# S1C31W74 register map
Vendor: Epson; Series: S1C31W74; File version: 1.11
CPU: CM0PLUS r0p1, little endian, MPU, no FPU, VTOR, 2 interrupt priority bits
Registers are 16-bit, read-write, reset 0x0 unless marked. A register's access mark holds for its fields unless they carry their own. Offsets are from the block's base; [hi:lo] are bit positions; {n}, {i} and the like mark numbered series; 'fields as' and 'values as' point back to an identical list.

## UPMUX — Universal port multiplexer control
Base 0x40000300
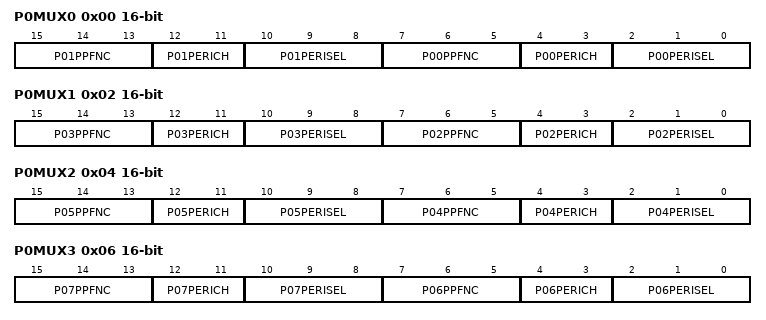
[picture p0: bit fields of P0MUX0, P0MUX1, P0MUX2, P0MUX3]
0x00 P0MUX0 — P00_01 Universal Port Multiplexer Setting Register
  [15:13] P01PPFNC — Assign pin function
  [12:11] P01PERICH — Assign Peripheral channel
  [10:8] P01PERISEL — Assign peripheral
  [7:5] P00PPFNC — Assign pin function
  [4:3] P00PERICH — Assign Peripheral channel
  [2:0] P00PERISEL — Assign peripheral
0x02 P0MUX1 — P02_03 Universal Port Multiplexer Setting Register
  [15:13] P03PPFNC — Assign pin function
  [12:11] P03PERICH — Assign peripheral channel
  [10:8] P03PERISEL — Assign peripheral
  [7:5] P02PPFNC — Assign pin function
  [4:3] P02PERICH — Assign Peripheral channel
  [2:0] P02PERISEL — Assign peripheral
0x04 P0MUX2 — P04_05 Universal Port Multiplexer Setting Register
  [15:13] P05PPFNC — Assign pin function
  [12:11] P05PERICH — Assign Peripheral channel
  [10:8] P05PERISEL — Assign peripheral
  [7:5] P04PPFNC — Assign pin function
  [4:3] P04PERICH — Assign Peripheral channel
  [2:0] P04PERISEL — Assign peripheral
0x06 P0MUX3 — P06_07 Universal Port Multiplexer Setting Register
  [15:13] P07PPFNC — Assign pin function
  [12:11] P07PERICH — Assign Peripheral channel
  [10:8] P07PERISEL — Assign peripheral
  [7:5] P06PPFNC — Assign pin function
  [4:3] P06PERICH — Assign Peripheral channel
  [2:0] P06PERISEL — Assign peripheral
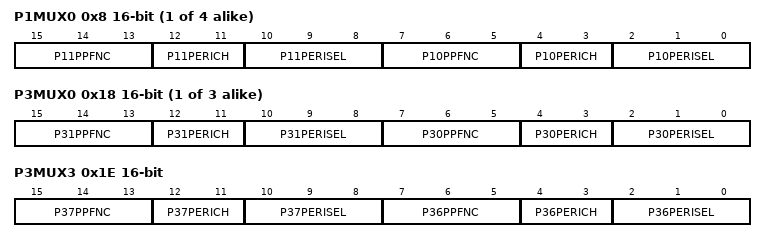
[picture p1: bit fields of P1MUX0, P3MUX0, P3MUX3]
{0x8+2i} P1MUX{i} (i=0..3) — P{2i+10}_{2i+11} Universal Port Multiplexer Setting Register
  [15:13] P{2i+11}PPFNC — Assign pin function
  [12:11] P{2i+11}PERICH — Assign Peripheral channel
  [10:8] P{2i+11}PERISEL — Assign peripheral
  [7:5] P{2i+10}PPFNC — Assign pin function
  [4:3] P{2i+10}PERICH — Assign Peripheral channel
  [2:0] P{2i+10}PERISEL — Assign peripheral
{0x18+2i} P3MUX{i} (i=0..2) — P{2i+30}_{2i+31} Universal Port Multiplexer Setting Register
  [15:13] P{2i+31}PPFNC — Assign pin function
  [12:11] P{2i+31}PERICH — Assign peripheral channel
  [10:8] P{2i+31}PERISEL — Assign peripheral
  [7:5] P{2i+30}PPFNC — Assign pin function
  [4:3] P{2i+30}PERICH — Assign peripheral channel
  [2:0] P{2i+30}PERISEL — Assign peripheral
0x1E P3MUX3 — P36_37 Universal Port Multiplexer Setting Register
  [15:13] P37PPFNC — Assign pin function
  [12:11] P37PERICH — Assign Peripheral channel
  [10:8] P37PERISEL — Assign peripheral
  [7:5] P36PPFNC — Assign pin function
  [4:3] P36PERICH — Assign Peripheral channel
  [2:0] P36PERISEL — Assign peripheral

## SPIA_0 — Synchronous serial interface control
Base 0x400003B0
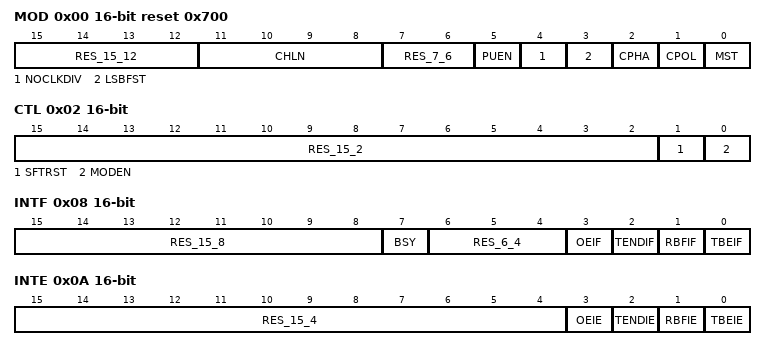
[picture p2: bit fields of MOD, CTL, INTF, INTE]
0x00 MOD reset 0x700 — Mode Register
  [15:12] RES_15_12 ro — Reserved bits
  [11:8] CHLN — Data length select
    {v}={v+1}_BITS (v=1..15)
  [7:6] RES_7_6 ro — Reserved bits
  [5] PUEN — #SPISS, SPICLK (input), SDI pull-up, pull-down enable
    0=DISABLE (Disable pull-up/down); 1=ENABLE (Enable pull-up/down)
  [4] NOCLKDIV — No USE T16 underflow pulse
    0=USE_T16; 1=NO_USE_T16
  [3] LSBFST — LSB first mode select
    0=MSB_FIRST; 1=LSB_FIRST (SB first)
  [2] CPHA — Clock phase select
  [1] CPOL — Clock polarity select
  [0] MST — Master mode select
    0=SLAVE (Slave mode); 1=MASTER (Master mode)
0x02 CTL — Control Register
  [15:2] RES_15_2 ro — Reserved bits
  [1] SFTRST write-1-sets — Soft reset
    on write: 0=NON (No effect); 1=RESET (Issue software reset) | on read: 0=STOPPED (Software reset has finished (During normal operation)); 1=RUNNING (Software reset is executing)
  [0] MODEN — SPI enable
    0=DISABLE (Disable SPIA operations (In master mode, the operating clock is stopped)); 1=ENABLE (Enable SPIA operations (In master mode, the operating clock is supplied))
0x04 TXD — Transmit Data Register
  [15:0] TXD — Transmit buffer
0x06 RXD ro — Receive Data Register
  [15:0] RXD — Receive buffer
0x08 INTF — Interrupt Flag Register
  [15:8] RES_15_8 ro — Reserved bits
  [7] BSY ro — Transfer Busy / Slave Selected
    0=IDLE; 1=BUSY (Transmit/receive busy (master mode), #SPISSn = Low level (slave mode))
  [6:4] RES_6_4 ro — Reserved bits
  [3] OEIF ro write-1-clears — Receive over write error flag
    0=NOT_OCCURED (No cause of interrupt occurred); 1=OCCURED (Cause of interrupt occurred)
  [2] TENDIF ro write-1-clears — Transfer End interrupt flag
    values as OEIF
  [1] RBFIF ro — Receive buffer full interrupt flag
    values as OEIF
  [0] TBEIF ro — Transmit buffer empty interrupt flag
    values as OEIF
0x0A INTE — Interrupt Enable Register
  [15:4] RES_15_4 ro — Reserved bits
  [3] OEIE — Receive over write error interrupt enable
    0=DISABLE; 1=ENABLE
  [2] TENDIE — Transfer end interrupt enable
    0=DISABLE; 1=ENABLE
  [1] RBFIE — Receive buffer full interrupt enable
    0=DISABLE; 1=ENABLE
  [0] TBEIE — Transmit buffer empty interrupt enable
    0=DISABLE; 1=ENABLE
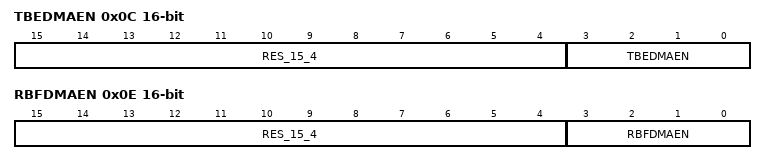
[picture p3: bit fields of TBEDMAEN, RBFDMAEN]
0x0C TBEDMAEN — TBE DMA Enable Register
  [15:4] RES_15_4 ro — Reserved bits
  [3:0] TBEDMAEN — TBE DMA ch3 request enable
0x0E RBFDMAEN — RBF DMA Enable Register
  [15:4] RES_15_4 ro — Reserved bits
  [3:0] RBFDMAEN — RBF DMA ch3 request enable
